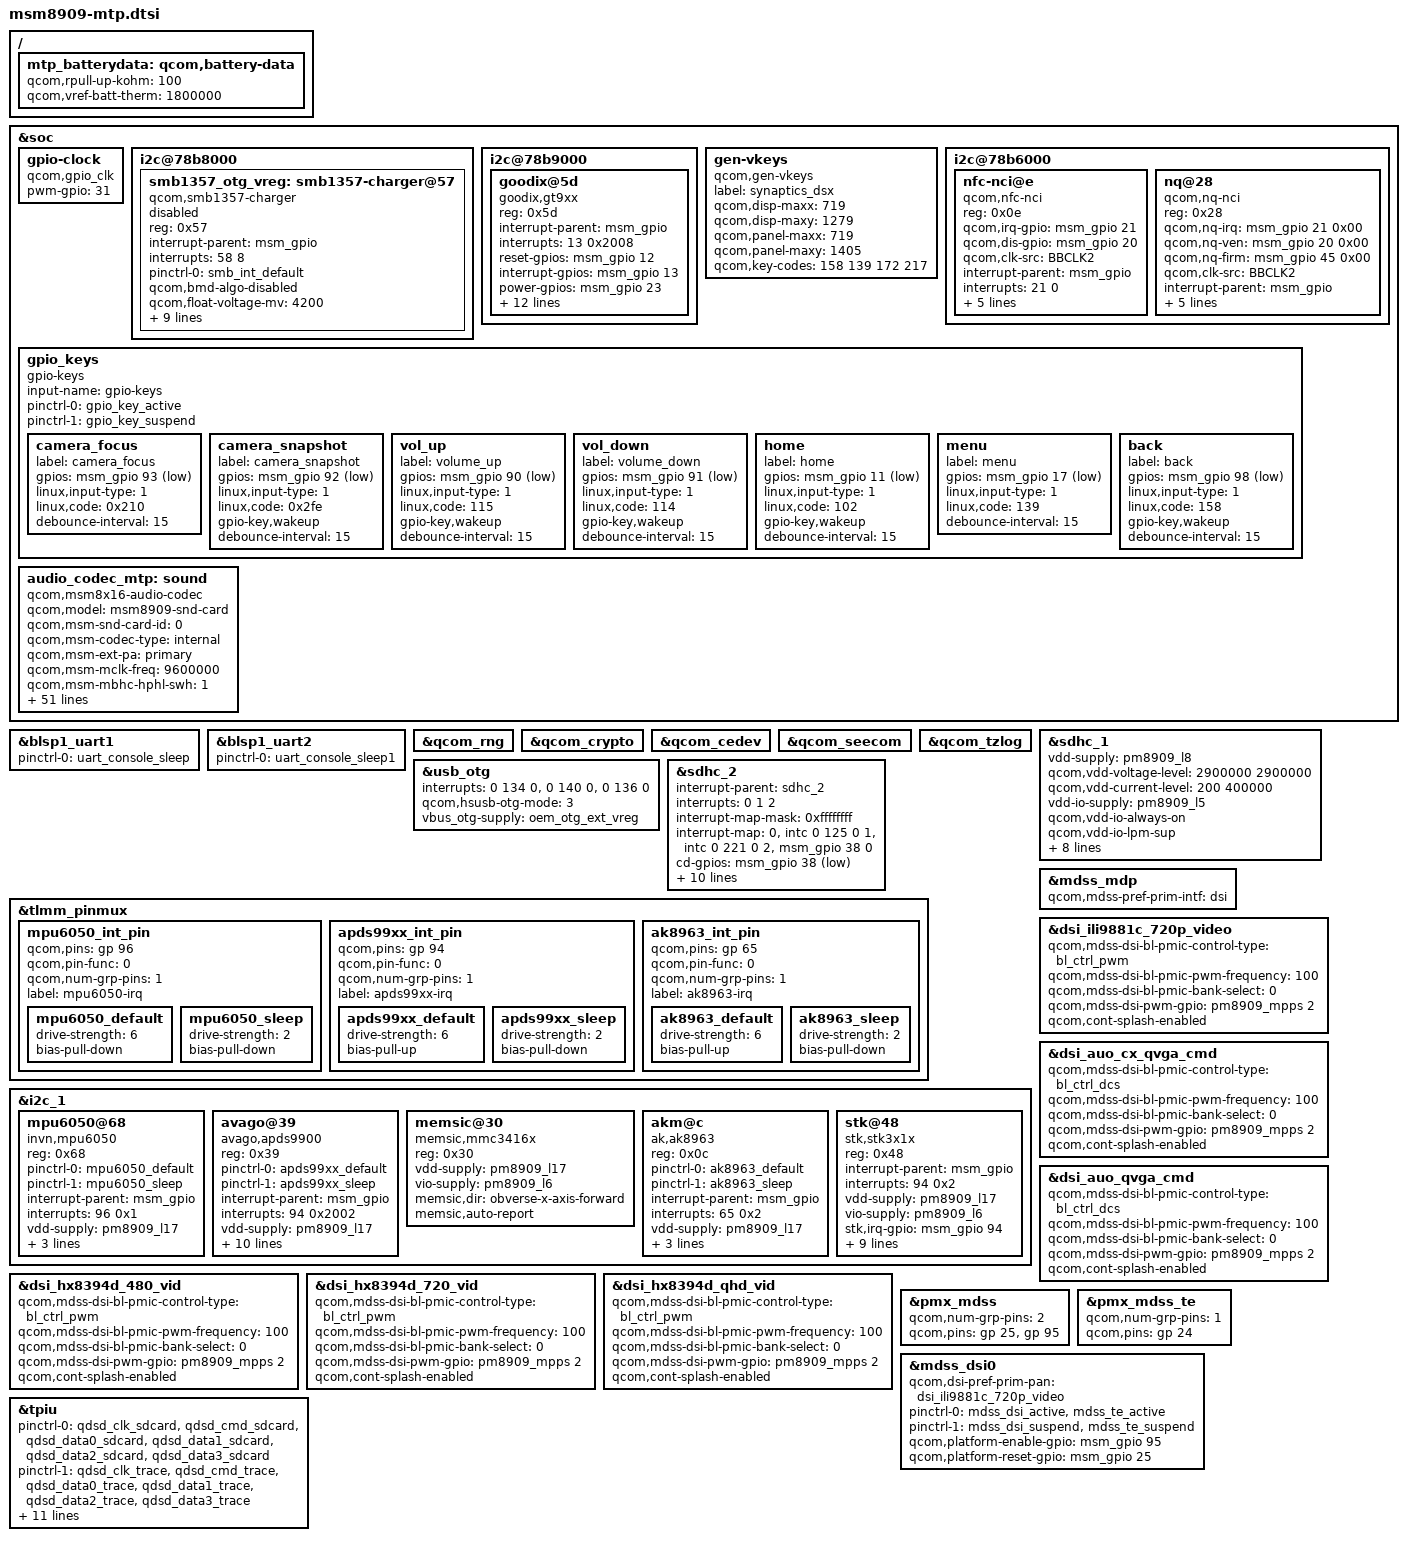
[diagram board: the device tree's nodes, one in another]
/* Copyright (c) 2014-2015, The Linux Foundation. All rights reserved.
 *
 * This program is free software; you can redistribute it and/or modify
 * it under the terms of the GNU General Public License version 2 and
 * only version 2 as published by the Free Software Foundation.
 *
 * This program is distributed in the hope that it will be useful,
 * but WITHOUT ANY WARRANTY; without even the implied warranty of
 * MERCHANTABILITY or FITNESS FOR A PARTICULAR PURPOSE.  See the
 * GNU General Public License for more details.
 */

#include "msm8909.dtsi"
#include "msm8909-pinctrl.dtsi"
#include "msm8909-camera-sensor-mtp.dtsi"
#include "msm8909-regulator.dtsi"

&soc {
       gpio-clock {
               compatible = "qcom,gpio_clk";
               pwm-gpio = <31>;
       };

	/*
	 * DT node to add support for SMB135x charger and integrate
	 * with VM-BMS.
	 */
	i2c@78b8000 {
		smb1357_otg_vreg: smb1357-charger@57 {
			compatible = "qcom,smb1357-charger";
			reg = <0x57>;
			interrupt-parent = <&msm_gpio>;
			interrupts = <58 8>;
			pinctrl-names = "default";
			pinctrl-0 = <&smb_int_default>;

			qcom,bmd-algo-disabled;
			qcom,float-voltage-mv = <4200>;
			qcom,charging-timeout = <1536>;
			qcom,recharge-thresh-mv = <100>;
			regulator-name = "smb1357_otg_vreg";
			qcom,soft-vfloat-comp-disabled;
			qcom,thermal-mitigation = <1500 700 600 0>;

			qcom,bms-psy-name = "bms";

			/*
			 * Disable SMB1357 based charging termination as BMS
			 * controls charging.
			 */
			qcom,iterm-disabled;

			/*
			 * Disable charge inhibit feature to start chargin on
			 * charger insertion independent of battery voltage.
			 */
			qcom,inhibit-disabled;

			/* BMS is controlling charging/re-charge */
			qcom,bms-controlled-charging;

			/*
			 * To enable charger node:
			 * set status = "ok" and
			 * add 'qcom,use-external-charger' to pm8909_chg node
			 */
			status = "disabled";
		};
	};

	i2c@78b9000 { /* BLSP1 QUP5 */
		goodix@5d {
			compatible = "goodix,gt9xx";
			reg = <0x5d>;
			interrupt-parent = <&msm_gpio>;
			interrupts = <13 0x2008>;
			reset-gpios = <&msm_gpio 12 0x0>;
			interrupt-gpios = <&msm_gpio 13 0x2008>;
			power-gpios = <&msm_gpio 23 0x0>;
			vcc-i2c-supply = <&pm8909_l6>;
			goodix,panel-coords = <0 0 719 1405>;
			goodix,display-coords = <0 0 719 1279>;
			goodix,button-map= <139 172 158>;
			goodix,enable-power-off;
			//goodix,product-id = "9147";       joseph modified  20160309
			goodix,fw_name = "gtp_fw.bin";
			pinctrl-names = "pmx_ts_active","pmx_ts_suspend";
			pinctrl-0 = <&ts_int_active &ts_reset_active>;
			pinctrl-1 = <&ts_int_suspend &ts_reset_suspend>;
			goodix,cfg-data0 = [
			44 DA 02 05 05 05 35 C1 01 09
			28 08 48 35 03 05 00 00 FF 7F
			10 50 85 14 17 1A 14 92 00 0A
			31 2F D3 07 03 00 00 A2 33 1D
			00 01 00 00 00 1E 00 09 10 00
			2A 1E 50 94 C5 02 00 0E 00 04
			B1 21 00 96 28 00 7F 31 00 6F
			3B 00 60 48 00 60 10 30 48 00
			F0 4A 3A FF EF 27 00 00 00 00
			00 01 1C 19 17 0F 01 00 01 0F
			0F 03 04 10 42 8F 0F 19 00 00
			46 37 08 0A 0C 0E 10 12 14 16
			18 1A 00 00 00 00 00 00 00 00
			00 00 00 00 00 00 00 00 00 00
			00 00 08 20 0A 1F 0C 1E 0E 1D
			22 05 24 04 28 00 29 02 2A 06
			00 00 00 00 00 00 00 00 00 00
			00 FF FF FF FF FF FF FF FF AF
			FF FF FF FF 87 01
			];
			goodix,have-touch-key;
			goodix,driver-send-cfg;
		};
	};

	gen-vkeys {
		compatible = "qcom,gen-vkeys";
		label = "synaptics_dsx";
		qcom,disp-maxx = <719>;
		qcom,disp-maxy = <1279>;
		qcom,panel-maxx = <719>;
		qcom,panel-maxy = <1405>;
		qcom,key-codes = <158 139 172 217>;
	};

	i2c@78b6000 { /* BLSP1 QUP2 */
		nfc-nci@e {
			compatible = "qcom,nfc-nci";
			reg = <0x0e>;
			qcom,irq-gpio = <&msm_gpio 21 0x00>;
			qcom,dis-gpio = <&msm_gpio 20 0x00>;
			qcom,clk-src = "BBCLK2";
			interrupt-parent = <&msm_gpio>;
			interrupts = <21 0>;
			interrupt-names = "nfc_irq";
			pinctrl-names = "nfc_active","nfc_suspend";
			pinctrl-0 = <&nfc_int_active &nfc_disable_active>;
			pinctrl-1 = <&nfc_int_suspend &nfc_disable_suspend>;
			qcom,clk-gpio = <&pm8909_gpios 2 0>;
			clocks = <&clock_rpm clk_bb_clk2_pin>;
			clock-names = "ref_clk";
		};
		nq@28 {
			compatible = "qcom,nq-nci";
			reg = <0x28>;
			qcom,nq-irq = <&msm_gpio 21 0x00>;
			qcom,nq-ven = <&msm_gpio 20 0x00>;
			qcom,nq-firm = <&msm_gpio 45 0x00>;
			qcom,clk-src = "BBCLK2";
			interrupt-parent = <&msm_gpio>;
			interrupts = <21 0>;
			interrupt-names = "nfc_irq";
			pinctrl-names = "nfc_active","nfc_suspend";
			pinctrl-0 = <&nfc_int_active &nfc_disable_active>;
			pinctrl-1 = <&nfc_int_suspend &nfc_disable_suspend>;
			clocks = <&clock_rpm clk_bb_clk2_pin>;
			clock-names = "ref_clk";
		};
	};

	gpio_keys {
		compatible = "gpio-keys";
		input-name = "gpio-keys";
		pinctrl-names = "tlmm_gpio_key_active","tlmm_gpio_key_suspend";
		pinctrl-0 = <&gpio_key_active>;
		pinctrl-1 = <&gpio_key_suspend>;

		camera_focus {
			label = "camera_focus";
			gpios = <&msm_gpio 93 0x1>;
			linux,input-type = <1>;
			linux,code = <0x210>;
		//	gpio-key,wakeup;	//law:del for system sleep abnormal,before modify sleep-current is 22mA ,after sleep-current is 7mA 2015-12-19
			debounce-interval = <15>;
		};

		camera_snapshot {
			label = "camera_snapshot";
			gpios = <&msm_gpio 92 0x1>;
			linux,input-type = <1>;
			linux,code = <0x2fe>;
			gpio-key,wakeup;
			debounce-interval = <15>;
		};

		vol_up {
			label = "volume_up";
			gpios = <&msm_gpio 90 0x1>;
			linux,input-type = <1>;
			linux,code = <115>;
			gpio-key,wakeup;
			debounce-interval = <15>;
		};

		vol_down {
			label = "volume_down";
			gpios = <&msm_gpio 91 0x1>;
			linux,input-type = <1>;
			linux,code = <114>;
			gpio-key,wakeup;
			debounce-interval = <15>;
		};
		home {
			label = "home";
			gpios = <&msm_gpio 11 0x1>;
			linux,input-type = <1>;
			linux,code = <102>;
			gpio-key,wakeup;
			debounce-interval = <15>;
		};

		menu {
			label = "menu";
			gpios = <&msm_gpio 17 0x1>;
			linux,input-type = <1>;
			linux,code = <139>;
		//	gpio-key,wakeup;    //law:del for system sleep abnormal,before modify sleep-current is 22mA ,after sleep-current is 7mA 2015-12-19
			debounce-interval = <15>;
		};

		back {
			label = "back";
			gpios = <&msm_gpio 98 0x1>;
			linux,input-type = <1>;
			linux,code = <158>;
			gpio-key,wakeup;
			debounce-interval = <15>;
		};
	};

	audio_codec_mtp: sound {
		compatible = "qcom,msm8x16-audio-codec";
		qcom,model = "msm8909-snd-card";
		qcom,msm-snd-card-id = <0>;
		qcom,msm-codec-type = "internal";
		qcom,msm-ext-pa = "primary";
		qcom,msm-mclk-freq = <9600000>;
		qcom,msm-mbhc-hphl-swh = <1>;		/*joseph modified*/
		qcom,msm-mbhc-gnd-swh = <0>;
		qcom,msm-hs-micbias-type = "internal";
		qcom,msm-micbias1-ext-cap;
		qcom,audio-routing =
			"RX_BIAS", "MCLK",
			"SPK_RX_BIAS", "MCLK",
			"INT_LDO_H", "MCLK",
			"MIC BIAS Internal1", "Handset Mic",		/**joseph modified for internal bias**/
			"MIC BIAS Internal2", "Headset Mic",
			"MIC BIAS Internal1", "Secondary Mic",
			"AMIC1", "MIC BIAS Internal1",
			"AMIC2", "MIC BIAS Internal2",
			"AMIC3", "MIC BIAS Internal1";
		pinctrl-names = "cdc_lines_act",
				"cdc_lines_sus",
				"cross_conn_det_act",
				"cross_conn_det_sus";
		pinctrl-0 = <&cdc_pdm_lines_act>;
		pinctrl-1 = <&cdc_pdm_lines_sus>;
		pinctrl-2 = <&cross_conn_det_act>;
		pinctrl-3 = <&cross_conn_det_sus>;
		qcom,cdc-us-euro-gpios = <&msm_gpio 97 0>;
		asoc-platform = <&pcm0>, <&pcm1>, <&voip>, <&voice>,
				<&loopback>, <&compress>, <&hostless>,
				<&afe>, <&lsm>, <&routing>, <&lpa>,
				<&voice_svc>;
		asoc-platform-names = "msm-pcm-dsp.0", "msm-pcm-dsp.1",
				"msm-voip-dsp", "msm-pcm-voice", "msm-pcm-loopback",
				"msm-compress-dsp", "msm-pcm-hostless", "msm-pcm-afe",
				"msm-lsm-client", "msm-pcm-routing", "msm-pcm-lpa",
				"msm-voice-svc";
		asoc-cpu = <&dai_pri_auxpcm>, <&dai_hdmi>,
				<&dai_mi2s0>, <&dai_mi2s1>, <&dai_mi2s2>, <&dai_mi2s3>,
				<&sb_0_rx>, <&sb_0_tx>, <&sb_1_rx>, <&sb_1_tx>,
				<&sb_3_rx>, <&sb_3_tx>, <&sb_4_rx>, <&sb_4_tx>,
				<&bt_sco_rx>, <&bt_sco_tx>,<&bt_a2dp_rx>,
                                <&int_fm_rx>, <&int_fm_tx>,
				<&afe_pcm_rx>, <&afe_pcm_tx>, <&afe_proxy_rx>, <&afe_proxy_tx>,
				<&incall_record_rx>, <&incall_record_tx>, <&incall_music_rx>,
				<&incall_music_2_rx>;
		asoc-cpu-names = "msm-dai-q6-auxpcm.1", "msm-dai-q6-hdmi.8",
				"msm-dai-q6-mi2s.0", "msm-dai-q6-mi2s.1",
				"msm-dai-q6-mi2s.2", "msm-dai-q6-mi2s.3",
				"msm-dai-q6-dev.16384", "msm-dai-q6-dev.16385",
				"msm-dai-q6-dev.16386", "msm-dai-q6-dev.16387",
				"msm-dai-q6-dev.16390", "msm-dai-q6-dev.16391",
				"msm-dai-q6-dev.16392", "msm-dai-q6-dev.16393",
				"msm-dai-q6-dev.12288", "msm-dai-q6-dev.12289",
				"msm-dai-q6-dev.12290", "msm-dai-q6-dev.12292",
                                "msm-dai-q6-dev.12293", "msm-dai-q6-dev.224",
				"msm-dai-q6-dev.225", "msm-dai-q6-dev.241",
				"msm-dai-q6-dev.240", "msm-dai-q6-dev.32771",
				"msm-dai-q6-dev.32772", "msm-dai-q6-dev.32773",
                                "msm-dai-q6-dev.32770";
		asoc-codec = <&stub_codec>, <&pm8909_conga_dig>;
		asoc-codec-names = "msm-stub-codec.1", "tombak_codec";
	};
};

&blsp1_uart1 {
	status = "ok";
	pinctrl-names = "default";
	pinctrl-0 = <&uart_console_sleep>;
};

 /*add by evan.hai for ttyHSL1*/
&blsp1_uart2 {
        status = "ok";
        pinctrl-names = "default";
        pinctrl-0 = <&uart_console_sleep1>;
};

/ {
	mtp_batterydata: qcom,battery-data {
		qcom,rpull-up-kohm = <100>;
		qcom,vref-batt-therm = <1800000>;

		#include "batterydata-palladium.dtsi"
	};
};

&qcom_rng {
	status = "okay";
};

&qcom_crypto {
	status = "okay";
};

&qcom_cedev {
	status = "okay";
};

&qcom_seecom {
	status = "okay";
};

&qcom_tzlog {
	status = "okay";
};

&sdhc_1 {
	vdd-supply = <&pm8909_l8>;
	qcom,vdd-voltage-level = <2900000 2900000>;
	qcom,vdd-current-level = <200 400000>;

	vdd-io-supply = <&pm8909_l5>;
	qcom,vdd-io-always-on;
	qcom,vdd-io-lpm-sup;
	qcom,vdd-io-voltage-level = <1800000 1800000>;
	qcom,vdd-io-current-level = <200 60000>;

	pinctrl-names = "active", "sleep";
	pinctrl-0 = <&sdc1_clk_on &sdc1_cmd_on &sdc1_data_on>;
	pinctrl-1 = <&sdc1_clk_off &sdc1_cmd_off &sdc1_data_off>;

	qcom,bus-speed-mode = "HS200_1p8v", "DDR_1p8v";
	qcom,nonremovable;

	status = "ok";
};
//law---2016.4.14-11:47----modify for usb otg-------

&usb_otg {
        interrupts = <0 134 0>,<0 140 0>,<0 136 0>;
        interrupt-names = "core_irq", "async_irq", "phy_irq";

        qcom,hsusb-otg-mode = <3>;
        vbus_otg-supply = <&oem_otg_ext_vreg>;
};
//------------------end-----------------------------
&sdhc_2 {
	 #address-cells = <0>;
	interrupt-parent = <&sdhc_2>;
	interrupts = <0 1 2>;
	#interrupt-cells = <1>;
	interrupt-map-mask = <0xffffffff>;
	interrupt-map = <0 &intc 0 125 0
			1 &intc 0 221 0
			2 &msm_gpio 38 0>;
	interrupt-names = "hc_irq", "pwr_irq", "status_irq";
	cd-gpios = <&msm_gpio 38 0x1>;

	vdd-supply = <&pm8909_l11>;
	qcom,vdd-voltage-level = <1800000 2950000>;
	qcom,vdd-current-level = <15000 400000>;

	vdd-io-supply = <&pm8909_l12>;
	qcom,vdd-io-voltage-level = <1800000 2950000>;
	qcom,vdd-io-current-level = <200 50000>;

	pinctrl-names = "active", "sleep";
	pinctrl-0 = <&sdc2_clk_on &sdc2_cmd_on &sdc2_data_on &sdc2_cd_on>;
	pinctrl-1 = <&sdc2_clk_off &sdc2_cmd_off &sdc2_data_off &sdc2_cd_off>;

	status = "ok";
};

&tlmm_pinmux {
	mpu6050_int_pin {
		qcom,pins = <&gp 96>;
		qcom,pin-func = <0>;
		qcom,num-grp-pins = <1>;
		label = "mpu6050-irq";
		mpu6050_default: mpu6050_default {
			drive-strength = <6>;
			bias-pull-down;
		};
		mpu6050_sleep: mpu6050_sleep {
			drive-strength = <2>;
			bias-pull-down;
		};
	};

	apds99xx_int_pin {
		qcom,pins = <&gp 94>;
		qcom,pin-func = <0>;
		qcom,num-grp-pins = <1>;
		label = "apds99xx-irq";
		apds99xx_default: apds99xx_default {
			drive-strength = <6>;
			bias-pull-up;
		};
		apds99xx_sleep: apds99xx_sleep {
			drive-strength = <2>;
			bias-pull-down;
		};
	};

	ak8963_int_pin {
		qcom,pins = <&gp 65>;
		qcom,pin-func = <0>;
		qcom,num-grp-pins = <1>;
		label = "ak8963-irq";
		ak8963_default: ak8963_default {
			drive-strength = <6>;
			bias-pull-up;
		};
		ak8963_sleep: ak8963_sleep {
			drive-strength = <2>;
			bias-pull-down;
		};
	};
};

&i2c_1 { /* BLSP1 QUP1 */
	mpu6050@68 { /* Gyroscope and accelerometer sensor combo */
		compatible = "invn,mpu6050";
		reg = <0x68>;
		pinctrl-names = "mpu_default","mpu_sleep";
		pinctrl-0 = <&mpu6050_default>;
		pinctrl-1 = <&mpu6050_sleep>;
		interrupt-parent = <&msm_gpio>;
		interrupts = <96 0x1>;
		vdd-supply = <&pm8909_l17>;
		vlogic-supply = <&pm8909_l6>;
		invn,gpio-int = <&msm_gpio 96 0x1>;
		invn,place = "Portrait Down Back Side";
	};

	avago@39 { /* Ambient light and proximity sensor */
		compatible = "avago,apds9900";
		reg = <0x39>;
		pinctrl-names = "default","sleep";
		pinctrl-0 = <&apds99xx_default>;
		pinctrl-1 = <&apds99xx_sleep>;
		interrupt-parent = <&msm_gpio>;
		interrupts = <94 0x2002>;
		vdd-supply = <&pm8909_l17>;
		vio-supply = <&pm8909_l6>;
		avago,irq-gpio = <&msm_gpio 94 0x2002>;
		avago,ps-threshold = <600>;
		avago,ps-hysteresis-threshold = <500>;
		avago,ps-pulse = <8>;
		avago,ps-pgain = <0>;
		avago,als-B = <186>;
		avago,als-C = <75>;
		avago,als-D = <129>;
		avago,ga-value = <256>;
	};

	memsic@30 { /* Magnetic field sensor */
		compatible = "memsic,mmc3416x";
		reg = <0x30>;
		vdd-supply = <&pm8909_l17>;
		vio-supply = <&pm8909_l6>;
		memsic,dir = "obverse-x-axis-forward";
		memsic,auto-report;
	};

	akm@c { /* Magnetic field sensor */
		compatible = "ak,ak8963";
		reg = <0x0c>;
		pinctrl-names = "ak8963_default", "ak8963_sleep";
		pinctrl-0 = <&ak8963_default>;
		pinctrl-1 = <&ak8963_sleep>;
		interrupt-parent = <&msm_gpio>;
		interrupts = <65 0x2>;
		vdd-supply = <&pm8909_l17>;
		vio-supply = <&pm8909_l6>;
		ak,layout = <0x6>;
		ak,auto-report;
	};

	stk@48 {/*law modify for p-sensor--------2015.11.18-13:07*/
	  compatible = "stk,stk3x1x";
	  reg = <0x48>;
	  interrupt-parent = <&msm_gpio>;
	  interrupts = <94 0x2>;
	  vdd-supply = <&pm8909_l17>;
	  vio-supply = <&pm8909_l6>;
	  stk,irq-gpio = <&msm_gpio 94 0x02>;
	  stk,transmittance = <500>;
	  stk,state-reg = <0x00>;
	  stk,psctrl-reg = <0x71>;
	  stk,alsctrl-reg = <0x38>;
	  stk,ledctrl-reg = <0xFF>;
	  stk,wait-reg = <0x07>;
	  stk,ps-thdh = <1700>;
	  stk,ps-thdl = <1500>;
	  stk,use-fir;
	 };

};

#include "dsi-panel-auo-qvga-cmd.dtsi"
#include "dsi-panel-auo-cx-qvga-cmd.dtsi"
#include "dsi-panel-hx8394d-480p-video.dtsi"
#include "dsi-panel-hx8394d-720p-video.dtsi"
#include "dsi-panel-hx8394d-qhd-video.dtsi"
#include "dsi-panel-ili9881c-720p-video.dtsi"

&mdss_mdp {
	qcom,mdss-pref-prim-intf = "dsi";
};

&dsi_ili9881c_720p_video {
        qcom,mdss-dsi-bl-pmic-control-type = "bl_ctrl_pwm";
        qcom,mdss-dsi-bl-pmic-pwm-frequency = <100>;
        qcom,mdss-dsi-bl-pmic-bank-select = <0>;
        qcom,mdss-dsi-pwm-gpio = <&pm8909_mpps 2 0>;
        qcom,cont-splash-enabled;
};

&dsi_auo_cx_qvga_cmd {
        qcom,mdss-dsi-bl-pmic-control-type = "bl_ctrl_dcs";
        qcom,mdss-dsi-bl-pmic-pwm-frequency = <100>;
        qcom,mdss-dsi-bl-pmic-bank-select = <0>;
        qcom,mdss-dsi-pwm-gpio = <&pm8909_mpps 2 0>;
        qcom,cont-splash-enabled;
};

&dsi_auo_qvga_cmd {
        qcom,mdss-dsi-bl-pmic-control-type = "bl_ctrl_dcs";
        qcom,mdss-dsi-bl-pmic-pwm-frequency = <100>;
        qcom,mdss-dsi-bl-pmic-bank-select = <0>;
        qcom,mdss-dsi-pwm-gpio = <&pm8909_mpps 2 0>;
        qcom,cont-splash-enabled;
};

&dsi_hx8394d_480_vid {
        qcom,mdss-dsi-bl-pmic-control-type = "bl_ctrl_pwm";
        qcom,mdss-dsi-bl-pmic-pwm-frequency = <100>;
        qcom,mdss-dsi-bl-pmic-bank-select = <0>;
        qcom,mdss-dsi-pwm-gpio = <&pm8909_mpps 2 0>;
        qcom,cont-splash-enabled;
};

&dsi_hx8394d_720_vid {
	qcom,mdss-dsi-bl-pmic-control-type = "bl_ctrl_pwm";
	qcom,mdss-dsi-bl-pmic-pwm-frequency = <100>;
	qcom,mdss-dsi-bl-pmic-bank-select = <0>;
	qcom,mdss-dsi-pwm-gpio = <&pm8909_mpps 2 0>;
	qcom,cont-splash-enabled;
};

&dsi_hx8394d_qhd_vid {
	qcom,mdss-dsi-bl-pmic-control-type = "bl_ctrl_pwm";
	qcom,mdss-dsi-bl-pmic-pwm-frequency = <100>;
	qcom,mdss-dsi-bl-pmic-bank-select = <0>;
	qcom,mdss-dsi-pwm-gpio = <&pm8909_mpps 2 0>;
	qcom,cont-splash-enabled;
};

&pmx_mdss {
	qcom,num-grp-pins = <2>;
	qcom,pins = <&gp 25>, <&gp 95>;
};

&pmx_mdss_te {
	qcom,num-grp-pins = <1>;
	qcom,pins = <&gp 24>;
};

&mdss_dsi0 {
	qcom,dsi-pref-prim-pan = <&dsi_ili9881c_720p_video>;
	pinctrl-names = "mdss_default", "mdss_sleep";
	pinctrl-0 = <&mdss_dsi_active &mdss_te_active>;
	pinctrl-1 = <&mdss_dsi_suspend &mdss_te_suspend>;

	qcom,platform-enable-gpio = <&msm_gpio 95 0>;
	qcom,platform-reset-gpio = <&msm_gpio 25 0>;
	//qcom,platform-bklight-en-gpio = <&msm_gpio 37 0>;
};

/* CoreSight */
&tpiu {
	pinctrl-names = "sdcard", "trace", "swduart",
			"swdtrc", "jtag", "spmi";
	/* NIDnT */
	pinctrl-0 = <&qdsd_clk_sdcard &qdsd_cmd_sdcard
		     &qdsd_data0_sdcard &qdsd_data1_sdcard
		     &qdsd_data2_sdcard &qdsd_data3_sdcard>;
	pinctrl-1 = <&qdsd_clk_trace &qdsd_cmd_trace
		     &qdsd_data0_trace &qdsd_data1_trace
		     &qdsd_data2_trace &qdsd_data3_trace>;
	pinctrl-2 = <&qdsd_cmd_swduart &qdsd_data0_swduart
		     &qdsd_data1_swduart &qdsd_data2_swduart
		     &qdsd_data3_swduart>;
	pinctrl-3 = <&qdsd_clk_swdtrc &qdsd_cmd_swdtrc
		     &qdsd_data0_swdtrc &qdsd_data1_swdtrc
		     &qdsd_data2_swdtrc &qdsd_data3_swdtrc>;
	pinctrl-4 = <&qdsd_cmd_jtag &qdsd_data0_jtag
		     &qdsd_data1_jtag &qdsd_data2_jtag
		     &qdsd_data3_jtag>;
	pinctrl-5 = <&qdsd_clk_spmi &qdsd_cmd_spmi
		     &qdsd_data0_spmi &qdsd_data3_spmi>;
};
